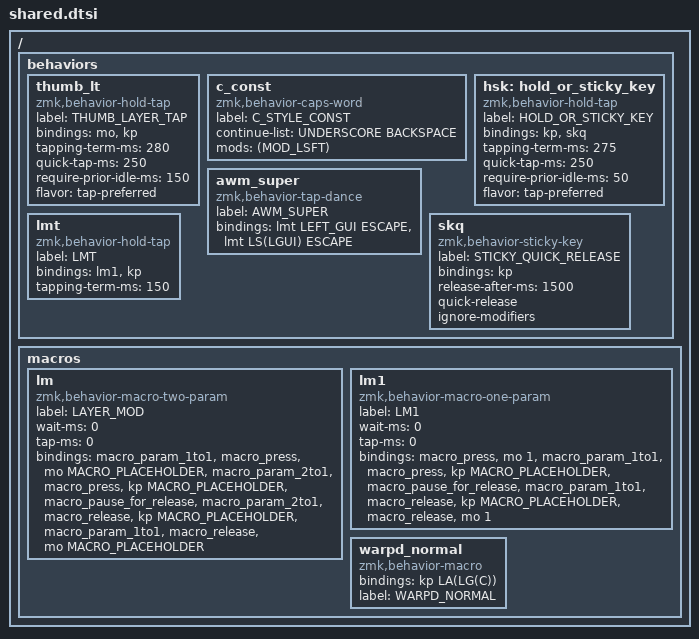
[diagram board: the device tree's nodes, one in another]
// vim: set ft=devicetree: commentstring=//%s:
#include <behaviors.dtsi>
#include <dt-bindings/zmk/keys.h>

/ {
    behaviors {
        thumb_lt: thumb_lt {
            compatible = "zmk,behavior-hold-tap";
            label = "THUMB_LAYER_TAP";
            bindings = <&mo>, <&kp>;

            #binding-cells = <2>;
            tapping-term-ms = <280>;
            quick-tap-ms = <250>;
            require-prior-idle-ms = <150>;
            flavor = "tap-preferred";
        };

        c_const: c_const {
            compatible = "zmk,behavior-caps-word";
            label = "C_STYLE_CONST";
            #binding-cells = <0>;
            continue-list = <UNDERSCORE BACKSPACE>;
            mods = <(MOD_LSFT)>;
        };

        hsk: hold_or_sticky_key {
            compatible = "zmk,behavior-hold-tap";
            label = "HOLD_OR_STICKY_KEY";
            bindings = <&kp>, <&skq>;

            #binding-cells = <2>;
            tapping-term-ms = <275>;
            quick-tap-ms = <250>;
            require-prior-idle-ms = <50>;
            flavor = "tap-preferred";
        };

        awm_super: awm_super {
            compatible = "zmk,behavior-tap-dance";
            label = "AWM_SUPER";
            #binding-cells = <0>;
            bindings = <&lmt LEFT_GUI ESCAPE>, <&lmt LS(LGUI) ESCAPE>;
        };

        skq: skq {
            compatible = "zmk,behavior-sticky-key";
            label = "STICKY_QUICK_RELEASE";
            bindings = <&kp>;
            #binding-cells = <1>;
            release-after-ms = <1500>;
            quick-release;
            ignore-modifiers;
        };

        lmt: lmt {
            compatible = "zmk,behavior-hold-tap";
            label = "LMT";
            bindings = <&lm1>, <&kp>;

            #binding-cells = <2>;
            tapping-term-ms = <150>;
        };
    };
    macros {
        lm: lm {
            label = "LAYER_MOD";
            compatible = "zmk,behavior-macro-two-param";
            wait-ms = <0>;
            tap-ms = <0>;
            #binding-cells = <2>;
            bindings =
                <&macro_param_1to1>,
                <&macro_press>,
                <&mo MACRO_PLACEHOLDER &macro_param_2to1>,
                <&macro_press>,
                <&kp MACRO_PLACEHOLDER>,
                <&macro_pause_for_release>,
                <&macro_param_2to1>,
                <&macro_release>,
                <&kp MACRO_PLACEHOLDER &macro_param_1to1>,
                <&macro_release>,
                <&mo MACRO_PLACEHOLDER>;
        };

        lm1: lm1 {
            compatible = "zmk,behavior-macro-one-param";
            label = "LM1";
            wait-ms = <0>;
            tap-ms = <0>;
            #binding-cells = <1>;
            bindings =
                <&macro_press>,
                <&mo 1 &macro_param_1to1>,
                <&macro_press>,
                <&kp MACRO_PLACEHOLDER>,
                <&macro_pause_for_release>,
                <&macro_param_1to1>,
                <&macro_release>,
                <&kp MACRO_PLACEHOLDER>,
                <&macro_release>,
                <&mo 1>;
        };

        warpd_normal: warpd_normal {
            compatible = "zmk,behavior-macro";
            #binding-cells = <0>;
            bindings = <&kp LA(LG(C))>;
            label = "WARPD_NORMAL";
        };
    };
};
